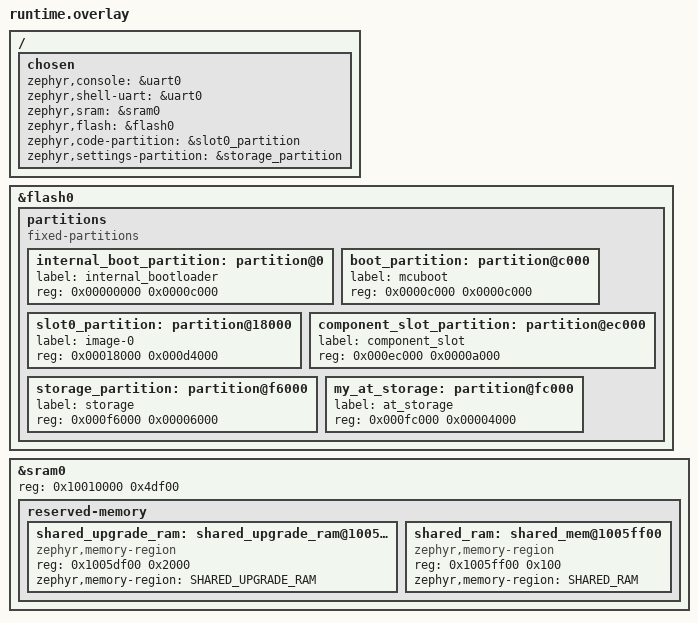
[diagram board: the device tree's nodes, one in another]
/ {
	chosen {
		zephyr,console = &uart0;
		zephyr,shell-uart = &uart0;
		zephyr,sram = &sram0;
		zephyr,flash = &flash0;
		zephyr,code-partition = &slot0_partition;
		zephyr,settings-partition = &storage_partition;
	};
};

&flash0 {
	partitions {
		compatible = "fixed-partitions";
		#address-cells = <1>;
		#size-cells = <1>;
		/delete-node/ partition@0;
		/delete-node/ partition@c000;
		/delete-node/ partition@18000;
		/delete-node/ partition@8a000;
		/delete-node/ partition@fc000;

		internal_boot_partition: partition@0 {
			label = "internal_bootloader";
			reg = <0x00000000 0x0000c000>;
		};

		boot_partition: partition@c000 {
			label = "mcuboot";
			reg = <0x0000c000 0x0000c000>;
		};

		slot0_partition: partition@18000 {
			label = "image-0";
			reg = <0x00018000 0x000d4000>;
		};

		component_slot_partition: partition@ec000 {
			label = "component_slot";
			reg = <0x000ec000 0x0000a000>;
		};

		storage_partition: partition@f6000 {
			label = "storage";
			reg = <0x000f6000 0x00006000>;
		};

		my_at_storage: partition@fc000 {
			label = "at_storage";
			reg = <0x000fc000 0x00004000>;
		};
	};
};

&sram0 {
	reg = <0x10010000 0x4df00>;

	reserved-memory {
		#address-cells = <1>;
		#size-cells = <1>;
		ranges;

		shared_upgrade_ram: shared_upgrade_ram@1005df00 {
			compatible = "zephyr,memory-region";
			reg = <0x1005df00 0x2000>;
			zephyr,memory-region = "SHARED_UPGRADE_RAM";
		};

		shared_ram: shared_mem@1005ff00 {
			compatible = "zephyr,memory-region";
			reg = <0x1005ff00 0x100>;
			zephyr,memory-region = "SHARED_RAM";
		};
	};
};
